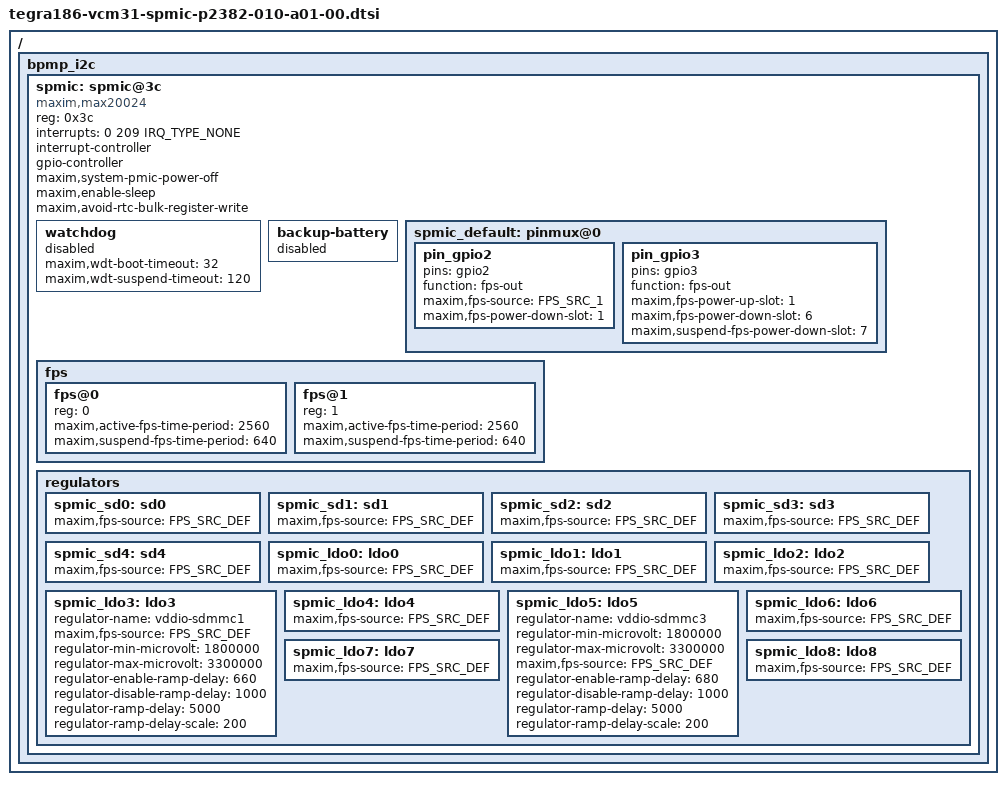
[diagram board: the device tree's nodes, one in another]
/*
 * Copyright (c) 2015 - 2016, NVIDIA CORPORATION.  All rights reserved.
 *
 * This program is free software; you can redistribute it and/or modify
 * it under the terms of the GNU General Public License as published by
 * the Free Software Foundation; either version 2 of the License, or
 * (at your option) any later version.
 *
 * This program is distributed in the hope that it will be useful, but WITHOUT
 * ANY WARRANTY; without even the implied warranty of MERCHANTABILITY or
 * FITNESS FOR A PARTICULAR PURPOSE.  See the GNU General Public License for
 * more details.
 */

#include <dt-bindings/mfd/max77620.h>
#include <dt-bindings/regulator/regulator.h>
#include <dt-bindings/gpio/tegra-gpio.h>
#include <dt-bindings/thermal/thermal.h>
#include <dt-bindings/interrupt-controller/irq.h>
#include "tegra186-platforms-simple-bus.dtsi"

/ {
	bpmp_i2c {
		spmic: spmic@3c {
			compatible = "maxim,max20024";
			reg = <0x3c>;

			interrupts = <0 209 IRQ_TYPE_NONE>;

			#interrupt-cells = <2>;
                        interrupt-controller;

			gpio-controller;
			#gpio-cells = <2>;

			maxim,system-pmic-power-off;
			maxim,enable-sleep;

			maxim,avoid-rtc-bulk-register-write;

			watchdog {
				status = "disabled";
				maxim,wdt-boot-timeout = <32>;
				maxim,wdt-suspend-timeout = <120>;
			};

			backup-battery {
				status = "disabled";
			};

			spmic_default: pinmux@0 {

				pin_gpio2 {
					pins = "gpio2";
					function = "fps-out";
					maxim,fps-source = <FPS_SRC_1>;
					maxim,fps-power-down-slot = <1>;
				};

				pin_gpio3 {
					pins = "gpio3";
					function = "fps-out";
					maxim,fps-power-up-slot = <1>;
					maxim,fps-power-down-slot = <6>;
					maxim,suspend-fps-power-down-slot = <7>;
				};
			};

			fps {
				#address-cells = <1>;
				#size-cells = <0>;
				fps@0 {
					reg = <0>;
					maxim,active-fps-time-period = <2560>;
					maxim,suspend-fps-time-period = <640>;
				};

				fps@1 {
					reg = <1>;
					maxim,active-fps-time-period = <2560>;
					maxim,suspend-fps-time-period = <640>;
				};
			};

			regulators {
				spmic_sd0: sd0 {
					maxim,fps-source = <FPS_SRC_DEF>;
				};

				spmic_sd1: sd1 {
					maxim,fps-source = <FPS_SRC_DEF>;
				};

				spmic_sd2: sd2 {
					maxim,fps-source = <FPS_SRC_DEF>;
				};

				spmic_sd3: sd3 {
					maxim,fps-source = <FPS_SRC_DEF>;
				};

				spmic_sd4: sd4 {
					maxim,fps-source = <FPS_SRC_DEF>;
				};

				spmic_ldo0: ldo0 {
					maxim,fps-source = <FPS_SRC_DEF>;
				};

				spmic_ldo1: ldo1 {
					maxim,fps-source = <FPS_SRC_DEF>;
				};

				spmic_ldo2: ldo2 {
					maxim,fps-source = <FPS_SRC_DEF>;
				};

				spmic_ldo3: ldo3 {
					regulator-name = "vddio-sdmmc1";
					maxim,fps-source = <FPS_SRC_DEF>;
					regulator-min-microvolt = <1800000>;
					regulator-max-microvolt = <3300000>;
					regulator-enable-ramp-delay = <660>;
					regulator-disable-ramp-delay = <1000>;
					regulator-ramp-delay = <5000>;
					regulator-ramp-delay-scale = <200>;
				};

				spmic_ldo4: ldo4 {
					maxim,fps-source = <FPS_SRC_DEF>;
				};

				spmic_ldo5: ldo5 {
					regulator-name = "vddio-sdmmc3";
					regulator-min-microvolt = <1800000>;
					regulator-max-microvolt = <3300000>;
					maxim,fps-source = <FPS_SRC_DEF>;
					regulator-enable-ramp-delay = <680>;
					regulator-disable-ramp-delay = <1000>;
					regulator-ramp-delay = <5000>;
					regulator-ramp-delay-scale = <200>;
				};

				spmic_ldo6: ldo6 {
					maxim,fps-source = <FPS_SRC_DEF>;
				};

				spmic_ldo7: ldo7 {
					maxim,fps-source = <FPS_SRC_DEF>;
				};

				spmic_ldo8: ldo8 {
					maxim,fps-source = <FPS_SRC_DEF>;
				};
			};
		};
	};
};
